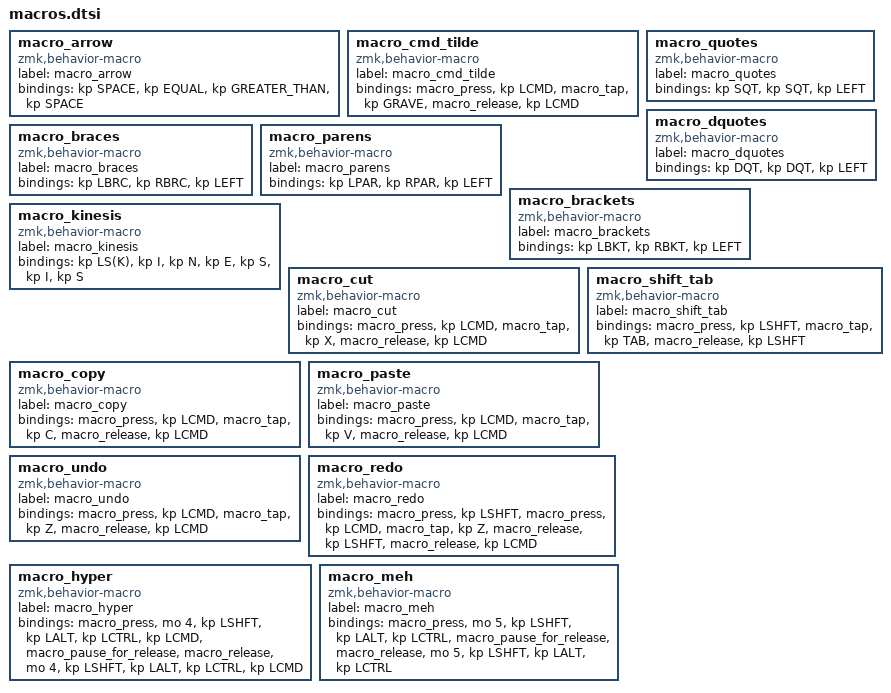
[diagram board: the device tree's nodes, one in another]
macro_arrow: macro_arrow{
compatible = "zmk,behavior-macro";
label = "macro_arrow";
#binding-cells = <0>;
bindings = <&kp SPACE>, <&kp EQUAL>, <&kp GREATER_THAN>, <&kp SPACE>;
};
macro_cmd_tilde: macro_cmd_tilde{
compatible = "zmk,behavior-macro";
label = "macro_cmd_tilde";
#binding-cells = <0>;
bindings = <&macro_press &kp LCMD>, <&macro_tap &kp GRAVE>, <&macro_release &kp LCMD>;
};
macro_quotes: macro_quotes{
compatible = "zmk,behavior-macro";
label = "macro_quotes";
#binding-cells = <0>;
bindings = <&kp SQT>, <&kp SQT>, <&kp LEFT>;
};
macro_dquotes: macro_dquotes{
compatible = "zmk,behavior-macro";
label = "macro_dquotes";
#binding-cells = <0>;
bindings = <&kp DQT>, <&kp DQT>, <&kp LEFT>;
};
macro_braces: macro_braces{
compatible = "zmk,behavior-macro";
label = "macro_braces";
#binding-cells = <0>;
bindings = <&kp LBRC>, <&kp RBRC>, <&kp LEFT>;
};
macro_parens: macro_parens{
compatible = "zmk,behavior-macro";
label = "macro_parens";
#binding-cells = <0>;
bindings = <&kp LPAR>, <&kp RPAR>, <&kp LEFT>;
};
macro_brackets: macro_brackets{
compatible = "zmk,behavior-macro";
label = "macro_brackets";
#binding-cells = <0>;
bindings = <&kp LBKT>, <&kp RBKT>, <&kp LEFT>;
};
macro_kinesis: macro_kinesis{
compatible = "zmk,behavior-macro";
label = "macro_kinesis";
#binding-cells = <0>;
bindings = <&kp LS(K)>, <&kp I>, <&kp N>, <&kp E>, <&kp S>, <&kp I>, <&kp S>;
};
macro_cut: macro_cut{
compatible = "zmk,behavior-macro";
label = "macro_cut";
#binding-cells = <0>;
bindings = <&macro_press &kp LCMD>, <&macro_tap &kp X>, <&macro_release &kp LCMD>;
};
macro_shift_tab: macro_shift_tab{
compatible = "zmk,behavior-macro";
label = "macro_shift_tab";
#binding-cells = <0>;
bindings = <&macro_press &kp LSHFT>, <&macro_tap &kp TAB>, <&macro_release &kp LSHFT>;
};
macro_copy: macro_copy{
compatible = "zmk,behavior-macro";
label = "macro_copy";
#binding-cells = <0>;
bindings = <&macro_press &kp LCMD>, <&macro_tap &kp C>, <&macro_release &kp LCMD>;
};
macro_paste: macro_paste{
compatible = "zmk,behavior-macro";
label = "macro_paste";
#binding-cells = <0>;
bindings = <&macro_press &kp LCMD>, <&macro_tap &kp V>, <&macro_release &kp LCMD>;
};
macro_undo: macro_undo{
compatible = "zmk,behavior-macro";
label = "macro_undo";
#binding-cells = <0>;
bindings = <&macro_press &kp LCMD>, <&macro_tap &kp Z>, <&macro_release &kp LCMD>;
};
macro_redo: macro_redo{
compatible = "zmk,behavior-macro";
label = "macro_redo";
#binding-cells = <0>;
bindings = <&macro_press &kp LSHFT>, <&macro_press &kp LCMD>, <&macro_tap &kp Z>, <&macro_release &kp LSHFT>, <&macro_release &kp LCMD>;
};
macro_hyper: macro_hyper{
compatible = "zmk,behavior-macro";
label = "macro_hyper";
#binding-cells = <0>;
bindings = <&macro_press &mo 4 &kp LSHFT &kp LALT &kp LCTRL &kp LCMD>, <&macro_pause_for_release>, <&macro_release &mo 4 &kp LSHFT &kp LALT &kp LCTRL &kp LCMD>;
};
macro_meh: macro_meh{
compatible = "zmk,behavior-macro";
label = "macro_meh";
#binding-cells = <0>;
bindings = <&macro_press &mo 5 &kp LSHFT &kp LALT &kp LCTRL>, <&macro_pause_for_release>, <&macro_release &mo 5 &kp LSHFT &kp LALT &kp LCTRL>;
};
